# SN32F400 register map
Vendor: SONiX Technology Co., Ltd.; Series: SN32F400; File version: 1.1
CPU: CM0 r0p0, little endian, no MPU, no FPU, 2 interrupt priority bits
Registers are 32-bit, read-write, reset 0x0 unless marked. A register's access mark holds for its fields unless they carry their own. Offsets are from the block's base; [hi:lo] are bit positions.

## SN_CRC — Cyclic Redundancy Check
Base 0x40038000
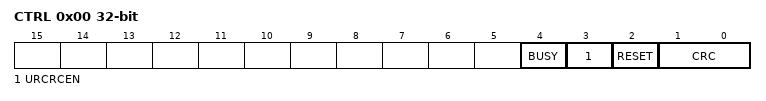
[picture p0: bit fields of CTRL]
0x00 CTRL — Offset:0x0 CRC Control register
  [4] BUSY ro — CRC calculation busy flag
    0=Idle/Finish (CRC calculation idle/finished); 1=Busy (CRC calculation is in process)
  [3] URCRCEN — CRC calculation for the User ROM enable bit
    0=Stop/Finish CRC calculation; 1=Enable (Start CRC calculation for the User ROM)
  [2] RESET — CRC Reset bit
    0=No (No effect); 1=Reset CRC circuit
  [1:0] CRC — CRC Polynomial
    0=CRC-16-CCITT (CRC-16-CCITT Polynomial); 1=CRC-16 (CRC-16 Polynomial); 2=CRC-32 (CRC-32 Polynomial)
0x04 DATA — Offset:0x4 CRC Data register
  [31:0] DATA — CRC Data

## SN_FLASH — FLASH Memory Control Registers
Base 0x40062000
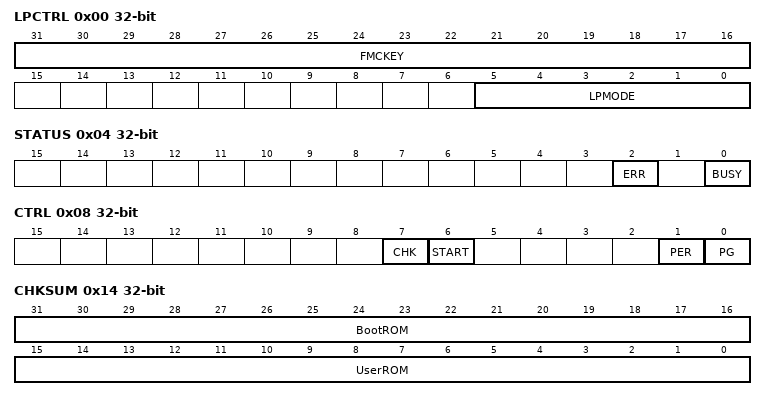
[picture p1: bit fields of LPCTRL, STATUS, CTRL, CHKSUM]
0x00 LPCTRL — Offset:0x00 Flash Low Power Control register
  [31:16] FMCKEY wo — FMC verify key
  [5:0] LPMODE — Flash Low Power mode selection bit
    0=HCLK is less than 24MHz; 41=HCLK is more than or equal to 24MHz, and less than or equal to 48MHz; 57=HCLK is more than 48MHz
0x04 STATUS — Offset:0x04 Flash Status register
  [2] ERR — Erase/Error flag
    0=No (No error); 1=Error (The address is illegal or over page boundary)
  [0] BUSY ro — Busy flag
    0=Idle (FMC is idle); 1=Busy (Flash operation is in process)
0x08 CTRL — Offset:0x08 Flash Control register
  [7] CHK — Checksum calculation chosen
    0=Disable checksum calcuation; 1=Enable (Trigger checksum calculation)
  [6] START — Start erase/program operation
    0=Stop/finish operation; 1=Start erase/program operation
  [1] PER — Page erase mode chosen bit
    0=Disable page erase mode; 1=Enable page erase mode
  [0] PG — Flash program mode chosen bit
    0=Disable Flash program mode; 1=Enable Flash program mode
0x0C DATA — Offset:0x0C Flash Data register
  [31:0] DATA — Flash data
0x10 ADDR — Offset:0x10 Flash Address register
  [31:0] ADDR — Flash address
0x14 CHKSUM ro — Offset:0x14 Flash Checksum register
  [31:16] BootROM — Checksum of Boot ROM
  [15:0] UserROM — Checksum of User ROM
0x20 WP — Offset:0x20 Flash Write Protect register
  [15:0] WP — Flash Write protect key

## SN_ACC — Atan, Div and Sqrt Function
Base 0x40076000
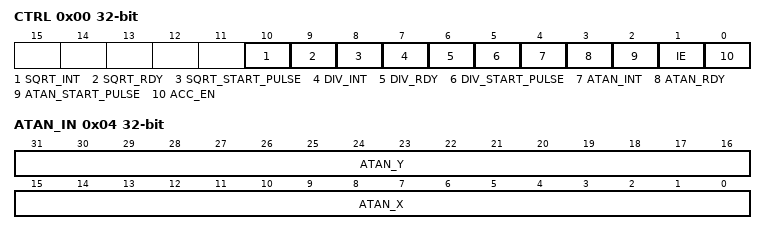
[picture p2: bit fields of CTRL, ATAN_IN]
0x00 CTRL — Offset:0x00 ACC Hardware Calculation Accelerator Control register
  [10] SQRT_INT — Square root interrupt signal
    0=None (No SQRT interrupt); 1=Meet (SQRT interrupt is triggered)
  [9] SQRT_RDY ro — Square root ready status
    0=Busy (SQRT is operating); 1=Idle (SQRT is not operating)
  [8] SQRT_START_PULSE — Square root operation trigger bit
    0=None (No action); 1=Trigger 1 pulse to start SRQT operating
  [7] DIV_INT — Division interrupt signal
    0=None (No DIV interrupt); 1=Meet (DIV interrupt is triggered)
  [6] DIV_RDY ro — Division ready status
    0=Busy (DIV is operating); 1=Idle (DIV is not operating)
  [5] DIV_START_PULSE — Division operation trigger bit
    0=None (No action); 1=Trigger 1 pulse to start DIV operating
  [4] ATAN_INT — Arctangent interrupt signal
    0=None (No ATAN interrupt); 1=Meet (ATAN interrupt is triggered)
  [3] ATAN_RDY ro — Arctangent ready status
    0=Busy (ATAN is operating); 1=Idle (ATAN is not operating)
  [2] ATAN_START_PULSE — Arctangent operation trigger bit
    0=None (No action); 1=Trigger 1 pulse to start ATAN operating
  [1] IE — Hardware calculation accelerator interrupt enable bit
    0=Disable ACC interrupt; 1=Enable ACC interrupt
  [0] ACC_EN — Hardware calculation accelerator enable bit
    0=Disable the hardware accelerator; 1=Enable the hardware accelerator
0x04 ATAN_IN — Offset:0x04 ACC Arctangent Input register
  [31:16] ATAN_Y — Arctangent y-axis input value in I16Q15 format
  [15:0] ATAN_X — Arctangent x-axis input value in I16Q15 format
0x08 ATAN_OUT — Offset:0x08 ACC Arctangent Output register
  [17:0] ATAN_OUT — Arctangent output value in I18Q15 format. Result is between -pi and pi
0x0C DIV_DVD — Offset:0x0C ACC Dividend Input for Division register
  [31:0] DIV_DVD — Dividend input for division in signed 32-bit format
0x10 DIV_DVS — Offset:0x10 ACC Divisor Input for Division register
  [15:0] DIV_DVS — Divisor input for division in signed 16-bit format
0x14 DIV_QUO — Offset:0x14 ACC Quotient Output of Division register
  [31:0] DIV_QUO — Quotient output of division in signed 32-bit format
0x18 DIV_REM — Offset:0x18 ACC Reminder Output of Division register
  [15:0] DIV_REM — Reminder output of division in signed 16-bit format
0x1C SQRT_IN — Offset:0x1C ACC Square Root Input register
  [31:0] SQRT_IN — Square root input value in unsigned 32-bit format
0x20 SQRT_OUT — Offset:0x20 ACC Square Root Output register
  [15:0] SQRT_OUT — Square root output value in unsigned 16-bit format
